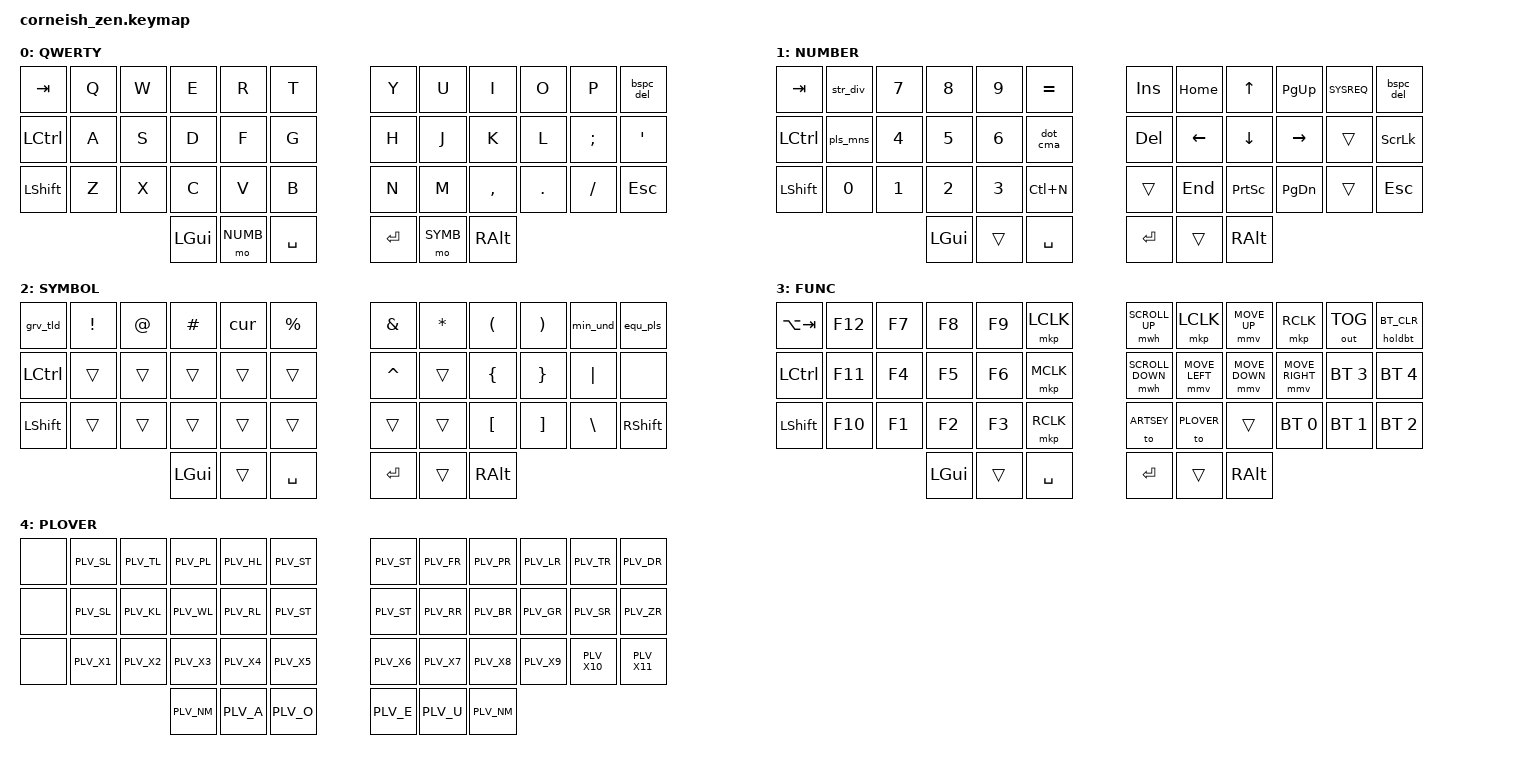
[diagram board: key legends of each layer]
#include <behaviors.dtsi>
#include <dt-bindings/zmk/keys.h>
#include <dt-bindings/zmk/bt.h>
#include <dt-bindings/zmk/mouse.h>
#include <dt-bindings/zmk/outputs.h>

#define MO_TO(layer) &mto layer layer   // Macro to apply momentary-layer-on-hold/go-to-layer-on-tap
#define HYPER LA(LS(LC(LGUI))) // definition for a hyper key
#define MEH   LA(LS(LCTRL))    // definition for a meta key

#define DEFAULT 0
#define NUMB    1
#define SYMB    2
#define FUNC    3
#define PLOVER  4
#define ARTSEY  5

#define ALL_NORMAL_LAYERS DEFAULT NUMB SYMB FUNC

#define LINUX_OS_LEAD &kp LC(LS(U))     // Linux specific sequence to initialize unicode
#define LINUX_OS_TRAIL &kp SPACE         // Linux specific sequence to terminate unicode
#define OS_LEAD LINUX_OS_LEAD
#define OS_TRAIL LINUX_OS_TRAIL

/ {
    chosen {
        zmk,matrix_transform = &default_transform;
    };
    macros {
      euro: euro {
        wait-ms = <5>;
        tap-ms = <5>;
        compatible = "zmk,behavior-macro";
        label = "UC_EURO";
        #binding-cells = <0>;
        bindings = <OS_LEAD &kp N2 &kp N0 &kp A &kp C OS_TRAIL>;
      };
      pound: pound {
        wait-ms = <5>;
        tap-ms = <5>;
        compatible = "zmk,behavior-macro";
        label = "UC_POUND";
        #binding-cells = <0>;
        bindings = <OS_LEAD &kp A &kp N3 OS_TRAIL>;
      };
      plover_toggle: plover_toggle {
        wait-ms = <5>;
        tap-ms = <5>;
        compatible = "zmk,behavior-macro";
        label = "PLOVER";
        #binding-cells = <0>;
        bindings = <&macro_press &kp E &kp R &kp F &kp V &kp O &kp L>, <&macro_release &kp E &kp R &kp F &kp V &kp O &kp L>;
      };
    };
    behaviors {
        holdbt: hold_bt {
            compatible = "zmk,behavior-hold-tap";
            label = "HBT";
            #binding-cells = <2>;
            flavor = "tap-preferred";
            tapping-term-ms = <2000>;
            quick-tap-ms = <200>;
            bindings = <&bt>, <&none>;
            hold-trigger-key-positions = <1>;
        };
        bspc_del: backspace_delete {
            compatible = "zmk,behavior-mod-morph";
            label = "BACKSPACE_DEL";
            #binding-cells = <0>;
            bindings = <&kp BACKSPACE>, <&kp DELETE>;
            mods = <(MOD_LSFT|MOD_RSFT)>;
            keep-mods = <(MOD_RSFT)>;
        };
        mto: momentary_to {
            compatible = "zmk,behavior-hold-tap";
            label = "MOMENTARY_TO";
            #binding-cells = <2>;
            flavor = "hold-preferred";
            tapping-term-ms = <200>;
            quick-tap-ms = <125>;
            bindings = <&mo>, <&to>;
        };
        slk: shift_lock {
            compatible = "zmk,behavior-tap-dance";
            label = "SHIFT_LOCK";
            #binding-cells = <0>;
            tapping-term-ms = <200>;
            bindings = <&kp LSHIFT>, <&kp CAPS>;
        };
        cur: currency {
            compatible = "zmk,behavior-tap-dance";
            label = "CURRENCY";
            #binding-cells = <0>;
            tapping-term-ms = <200>;
            bindings = <&kp DOLLAR>, <&pound>, <&euro>;
        };
        grv_tld: grave_tilde {
            compatible = "zmk,behavior-mod-morph";
            label = "GRAVE_TILDE";
            #binding-cells = <0>;
            bindings = <&kp GRAVE>, <&kp TILDE>;
            mods = <(MOD_LSFT|MOD_RSFT)>;
        };
        min_und: minus_underscore {
            compatible = "zmk,behavior-mod-morph";
            label = "MINUS_UNDERSCORE";
            #binding-cells = <0>;
            bindings = <&kp MINUS>, <&kp UNDER>;
            mods = <(MOD_LSFT|MOD_RSFT)>;
        };
        equ_pls: equal_plus {
            compatible = "zmk,behavior-mod-morph";
            label = "EQUAL_PLUS";
            #binding-cells = <0>;
            bindings = <&kp EQUAL>, <&kp PLUS>;
            mods = <(MOD_LSFT|MOD_RSFT)>;
        };
        pls_mns: plus_minus {
            compatible = "zmk,behavior-mod-morph";
            label = "PLUS_MINUS";
            #binding-cells = <0>;
            bindings = <&kp PLUS>, <&kp MINUS>;
            mods = <(MOD_LSFT|MOD_RSFT)>;
        };
        str_div: times_divide {
            compatible = "zmk,behavior-mod-morph";
            label = "TIMES_DIVIDE";
            #binding-cells = <0>;
            bindings = <&kp STAR>, <&kp FSLH>;
            mods = <(MOD_LSFT|MOD_RSFT)>;
        };
        dot_cma: dot_comma {
            compatible = "zmk,behavior-mod-morph";
            label = "DOT_COMMA";
            #binding-cells = <0>;
            bindings = <&kp DOT>, <&kp COMMA>;
            mods = <(MOD_LSFT|MOD_RSFT)>;
        };
    };
    /*                    KEY POSITIONS
      ╭────────────────────────╮ ╭────────────────────────╮
      │  0   1   2   3   4   5 │ │  6   7   8   9  10  11 │
      │ 12  13  14  15  16  17 │ │ 18  19  20  21  22  23 │
      │ 24  25  26  27  28  29 │ │ 30  31  32  33  34  35 │
      ╰───────────╮ 36  37  38 │ │ 39  40  41 ╭───────────╯
                  ╰────────────╯ ╰────────────╯            */
    combos {
        compatible = "zmk,combos";
        combo_reset {
            timeout-ms = <40>;
            key-positions = <26 27 28 31 32 33>;
            bindings = <&to DEFAULT>;
            global-quick-tap-ms = <200>;
        };
        combo_esc {
            layers = <ALL_NORMAL_LAYERS>;
            timeout-ms = <40>;
            key-positions = <2 3>;
            bindings = <&kp ESC>;
            global-quick-tap-ms = <200>;
        };
        combo_tab {
            layers = <ALL_NORMAL_LAYERS>;
            timeout-ms = <40>;
            key-positions = <2 3 4>;
            bindings = <&kp TAB>;
            global-quick-tap-ms = <200>;
        };
        combo_bktab {
              layers = <ALL_NORMAL_LAYERS>;
              timeout-ms = <40>;
              key-positions = <1 2 3 4>;
              bindings = <&kp LS(TAB)>;
              global-quick-tap-ms = <200>;
          };
        combo_space {
            layers = <ALL_NORMAL_LAYERS>;
            timeout-ms = <40>;
            key-positions = <14 15 16>;
            bindings = <&kp SPACE>;
            global-quick-tap-ms = <200>;
        };
        combo_bspcleft {
            layers = <ALL_NORMAL_LAYERS>;
            timeout-ms = <40>;
            key-positions = <13 14 15 16>;
            bindings = <&kp BACKSPACE>;
            global-quick-tap-ms = <200>;
        };
        combo_enterleft {
            layers = <ALL_NORMAL_LAYERS>;
            timeout-ms = <40>;
            key-positions = <26 27 28>;
            bindings = <&kp ENTER>;
            global-quick-tap-ms = <200>;
        };
        combo_enterleft_nu {
            layers = <ALL_NORMAL_LAYERS>;
            timeout-ms = <40>;
            key-positions = <4 16>;
            bindings = <&kp ENTER>;
            global-quick-tap-ms = <200>;
        };
        combo_caps {
            layers = <ALL_NORMAL_LAYERS>;
            timeout-ms = <40>;
            key-positions = <25 26 27 28>;
            bindings = <&kp CAPS>;
            global-quick-tap-ms = <200>;
        };
        combo_copy {
            layers = <ALL_NORMAL_LAYERS>;
            timeout-ms = <40>;
            key-positions = <36 37 38>;
            bindings = <&kp LC(C)>;
            global-quick-tap-ms = <200>;
        };
        combo_paste {
            layers = <ALL_NORMAL_LAYERS>;
            timeout-ms = <40>;
            key-positions = <37 38>;
            bindings = <&kp LC(V)>;
            global-quick-tap-ms = <200>;
        };

        combo_bspc {
            layers = <ALL_NORMAL_LAYERS>;
            timeout-ms = <40>;
            key-positions = <7 8 9>;
            bindings = <&kp BACKSPACE>;
            global-quick-tap-ms = <200>;
        };
        combo_enter {
            layers = <ALL_NORMAL_LAYERS>;
            timeout-ms = <40>;
            key-positions = <19 20 21>;
            bindings = <&kp ENTER>;
            global-quick-tap-ms = <200>;
        };
        combo_undo {
            layers = <ALL_NORMAL_LAYERS>;
            timeout-ms = <40>;
            key-positions = <31 32 33>;
            bindings = <&kp LC(Z)>;
            global-quick-tap-ms = <200>;
        };
        combo_redo {
            layers = <ALL_NORMAL_LAYERS>;
            timeout-ms = <40>;
            key-positions = <31 32 33 34>;
            bindings = <&kp LS(LC(Z))>;
            global-quick-tap-ms = <200>;
        };
        combo_undo_left {
            layers = <ALL_NORMAL_LAYERS>;
            timeout-ms = <40>;
            key-positions = <16 28>;
            bindings = <&kp LC(Z)>;
            global-quick-tap-ms = <200>;
        };
        combo_redo_left {
            layers = <ALL_NORMAL_LAYERS>;
            timeout-ms = <40>;
            key-positions = <15 27>;
            bindings = <&kp LS(LC(Z))>;
            global-quick-tap-ms = <200>;
        };
    };
    conditional_layers {
        compatible = "zmk,conditional-layers";
        tri_layer {
            if-layers = <NUMB SYMB>;
            then-layer = <FUNC>;
        };
    };
    keymap {
        compatible = "zmk,keymap";

        default_layer {
            label = "QWERTY";
// -----------------------------------------------------------------------------------------
// |  TAB |  Q  |  W  |  E  |  R  |  T  |---|  Y  |  U   |  I  |  O  |  P  | BKSP |
// | CTRL |  A  |  S  |  D  |  F  |  G  |---|  H  |  J   |  K  |  L  |  ;  |  '   |
// | SHFT |  Z  |  X  |  C  |  V  |  B  |---|  N  |  M   |  ,  |  .  |  /  | ESC  |
//                    | GUI | LWR | SPC |---| ENT | RSE  | ALT |
            bindings = <
   &kp TAB    &kp Q &kp W &kp E &kp R &kp T       &kp Y   &kp U    &kp I     &kp O   &kp P    &bspc_del
   &kp LCTRL  &kp A &kp S &kp D &kp F &kp G       &kp H   &kp J    &kp K     &kp L   &kp SEMI &kp SQT
   &kp LSHIFT &kp Z &kp X &kp C &kp V &kp B       &kp N   &kp M    &kp COMMA &kp DOT &kp FSLH &kp ESC
                    &kp LGUI &mo NUMB &kp SPACE   &kp RET &mo SYMB &kp RALT
            >;
        };
        lower_layer {
            label = "NUMBER";
// -----------------------------------------------------------------------------------------
// |  TAB | */ |  7  |  8  |  9  | =   |---| INS   | Home  |  UP | PG_UP | SYSREQ | BKSP   |
// | CTRL | +- |  4  |  5  |  6  | .,  |---| DEL   | LFT   | DWN | RGT   |        | SLCK   |
// | SHFT | 0  |  1  |  2  |  3  | new |---|       | End   | PRNT| PG_DN |        | ESC    |
//                   | GUI | □□□ | SP  |---| ENT   |       | ALT |/
            bindings = <
   &kp TAB    &str_div  &kp N7   &kp N8    &kp N9  &kp EQUAL    &kp INS  &kp HOME  &kp UP    &kp PG_UP  &kp SYSREQ  &bspc_del
   &kp LCTRL  &pls_mns  &kp N4   &kp N5    &kp N6  &dot_cma     &kp DEL  &kp LEFT  &kp DOWN  &kp RIGHT  &trans      &kp SLCK
   &kp LSHIFT &kp N0    &kp N1   &kp N2    &kp N3  &kp LC(N)    &trans   &kp END   &kp PSCRN &kp PG_DN  &trans      &kp ESC
                                 &kp LGUI  &trans  &kp SPACE    &kp RET  &trans    &kp RALT
            >;
        };
        raise_layer {
            label = "SYMBOL";
// -----------------------------------------------------------------------------------------
// |  `~  |  !  |  @  |  #  |  $  |  %   |---|  &  |  *  |  (  |  )  |  -_ |  =+  |
// | CTRL |     |     |     |     |  ^   |---|  ^  |     |  {  |  }  | "|" |      |
// | SHFT |     |     |     |     |      |---|     |     |  [  |  ]  |  \  | SHFT |
//                    | GUI |     |  SPC |---| ENT | □□□ | ALT |
            bindings = <
   &grv_tld   &kp EXCL &kp AT    &kp HASH &cur      &kp PRCNT   &kp AMPS  &kp STAR  &kp LPAR &kp RPAR &min_und  &equ_pls
   &kp LCTRL  &trans   &trans    &trans   &trans    &trans      &kp CARET &trans    &kp LBRC &kp RBRC &kp PIPE  &none
   &kp LSHIFT &trans   &trans    &trans   &trans    &trans      &trans    &trans    &kp LBKT &kp RBKT &kp BSLH  &kp RSHIFT
                    	         &kp LGUI &trans    &kp SPACE   &kp RET   &trans    &kp RALT
            >;
        };
        func_layer {
            label = "FUNC";
// -----------------------------------------------------------------------------------------
// | AltTAB | F12 | F7 | F8 | F9 | LCLK |---| SCRLUP | LCLK   | UP  | RCLK  | OUTTOG | BTCLR |
// | CTRL   | F11 | F4 | F5 | F6 | MCLK |---| SCRLDN | LEFT   | DN  | RIGHT | BT4    | BT5   |
// | SHFT   | F10 | F1 | F2 | F3 | RCLK |---| ARTSEY | PLOVER |     | BT1   | BT2    | BT3   |
//                  | GUI | □□ | SPC  |---| ENT    | □□□□□□ | ALT |
            bindings = <
   &kp LA(TAB) &kp F12 &kp F7 &kp F8   &kp F9  &mkp LCLK    &mwh SCROLL_UP   &mkp LCLK      &mmv MOVE_UP   &mkp RCLK       &out OUT_TOG &holdbt BT_CLR
   &kp LCTRL   &kp F11 &kp F4 &kp F5   &kp F6  &mkp MCLK    &mwh SCROLL_DOWN &mmv MOVE_LEFT &mmv MOVE_DOWN &mmv MOVE_RIGHT &bt BT_SEL 3 &bt BT_SEL 4
   &kp LSHIFT  &kp F10 &kp F1 &kp F2   &kp F3  &mkp RCLK    &to ARTSEY       &to PLOVER     &trans         &bt BT_SEL 0    &bt BT_SEL 1 &bt BT_SEL 2
                              &kp LGUI &trans  &kp SPACE    &kp RET          &trans         &kp RALT
            >;
        };
        plover_layer {
            label = "PLOVER";
// -----------------------------------------------------------------------------------------
// |    |  S  |  T  |  P  |  H  |  *  |---|  *  |  F   |  P  |  L  |  T  |  D   |
// |    |  S  |  K  |  W  |  R  |  *  |---|  *  |  R   |  B  |  G  |  S  |  Z   |
// |    |  X1 |  X2 |  X3 |  X4 |  X5 |---|  X6 |  X7  |  X8 |  X9 | X10 | X11  |
//                  |  #  |  A  |  I  |---|  E  |  U   |  #  |
            bindings = <
    &none  &kp PLV_SL  &kp PLV_TL   &kp PLV_PL  &kp PLV_HL  &kp PLV_ST     &kp PLV_ST  &kp PLV_FR  &kp PLV_PR  &kp PLV_LR   &kp PLV_TR  &kp PLV_DR
    &none  &kp PLV_SL  &kp PLV_KL   &kp PLV_WL  &kp PLV_RL  &kp PLV_ST     &kp PLV_ST  &kp PLV_RR  &kp PLV_BR  &kp PLV_GR   &kp PLV_SR  &kp PLV_ZR
    &none  &kp PLV_X1  &kp PLV_X2   &kp PLV_X3  &kp PLV_X4  &kp PLV_X5     &kp PLV_X6  &kp PLV_X7  &kp PLV_X8  &kp PLV_X9   &kp PLV_X10 &kp PLV_X11
                                    &kp PLV_NM  &kp PLV_A   &kp PLV_O      &kp PLV_E   &kp PLV_U   &kp PLV_NM
            >;
        };
    };
};



// Enable ARTSEY Left
#define ARTSEY_LEFT 1

// ARTS Row
#define KEY_A 4
#define KEY_R 3
#define KEY_T 2
#define KEY_S 1
// EYIO Row
#define KEY_E 16
#define KEY_Y 15
#define KEY_I 14
#define KEY_O 13

// Define Offsets
#define LEADING_NONES NONE(0, 0, 1)
#define MIDDLE_NONES NONE(0, 0, 8)
#define TRAILING_NONES NONE(0, 2, 5)

// Thumb buttons (used for BT combos)
#define THUMB_1 36
#define THUMB_2 37
#define THUMB_3 38

// Include main artsey.io keymap
#include "./artsey.dtsi"

